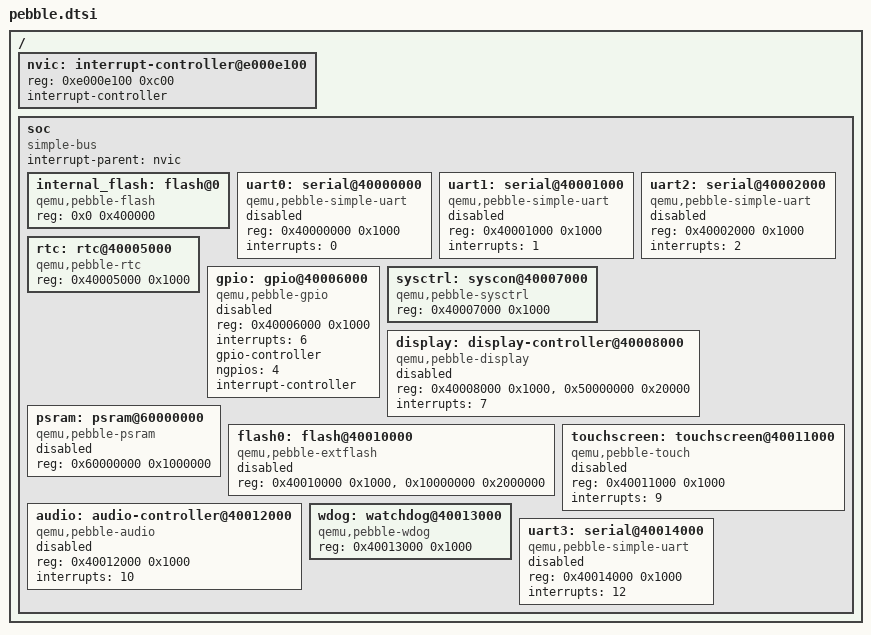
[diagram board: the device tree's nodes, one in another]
// SPDX-FileCopyrightText: 2026 Core Devices LLC
// SPDX-License-Identifier: (GPL-2.0-only OR BSD-2-Clause)

#include <dt-bindings/gpio/gpio.h>

/ {
	#address-cells = <1>;
	#size-cells = <1>;

	nvic: interrupt-controller@e000e100 {
		reg = <0xe000e100 0xc00>;
		interrupt-controller;
		#interrupt-cells = <1>;
		#address-cells = <0>;
	};

	soc {
		compatible = "simple-bus";
		#address-cells = <1>;
		#size-cells = <1>;
		interrupt-parent = <&nvic>;
		ranges;

		internal_flash: flash@0 {
			compatible = "qemu,pebble-flash";
			reg = <0x0 0x400000>;
		};

		uart0: serial@40000000 {
			compatible = "qemu,pebble-simple-uart";
			reg = <0x40000000 0x1000>;
			interrupts = <0>;
			status = "disabled";
		};

		uart1: serial@40001000 {
			compatible = "qemu,pebble-simple-uart";
			reg = <0x40001000 0x1000>;
			interrupts = <1>;
			status = "disabled";
		};

		uart2: serial@40002000 {
			compatible = "qemu,pebble-simple-uart";
			reg = <0x40002000 0x1000>;
			interrupts = <2>;
			status = "disabled";
		};

		rtc: rtc@40005000 {
			compatible = "qemu,pebble-rtc";
			reg = <0x40005000 0x1000>;
		};

		gpio: gpio@40006000 {
			compatible = "qemu,pebble-gpio";
			reg = <0x40006000 0x1000>;
			interrupts = <6>;
			gpio-controller;
			#gpio-cells = <2>;
			ngpios = <4>;
			interrupt-controller;
			#interrupt-cells = <2>;
			status = "disabled";
		};

		sysctrl: syscon@40007000 {
			compatible = "qemu,pebble-sysctrl", "syscon";
			reg = <0x40007000 0x1000>;
		};

		display: display-controller@40008000 {
			compatible = "qemu,pebble-display";
			reg = <0x40008000 0x1000>, <0x50000000 0x20000>;
			reg-names = "regs", "fb";
			interrupts = <7>;
			status = "disabled";
		};

		psram: psram@60000000 {
			compatible = "qemu,pebble-psram";
			reg = <0x60000000 0x1000000>;
			status = "disabled";
		};

		flash0: flash@40010000 {
			compatible = "qemu,pebble-extflash";
			reg = <0x40010000 0x1000>, <0x10000000 0x2000000>;
			reg-names = "regs", "mem";
			status = "disabled";
		};

		touchscreen: touchscreen@40011000 {
			compatible = "qemu,pebble-touch";
			reg = <0x40011000 0x1000>;
			interrupts = <9>;
			status = "disabled";
		};

		audio: audio-controller@40012000 {
			compatible = "qemu,pebble-audio";
			reg = <0x40012000 0x1000>;
			interrupts = <10>;
			#sound-dai-cells = <0>;
			status = "disabled";
		};

		wdog: watchdog@40013000 {
			compatible = "qemu,pebble-wdog";
			reg = <0x40013000 0x1000>;
		};

		uart3: serial@40014000 {
			compatible = "qemu,pebble-simple-uart";
			reg = <0x40014000 0x1000>;
			interrupts = <12>;
			status = "disabled";
		};
	};
};
